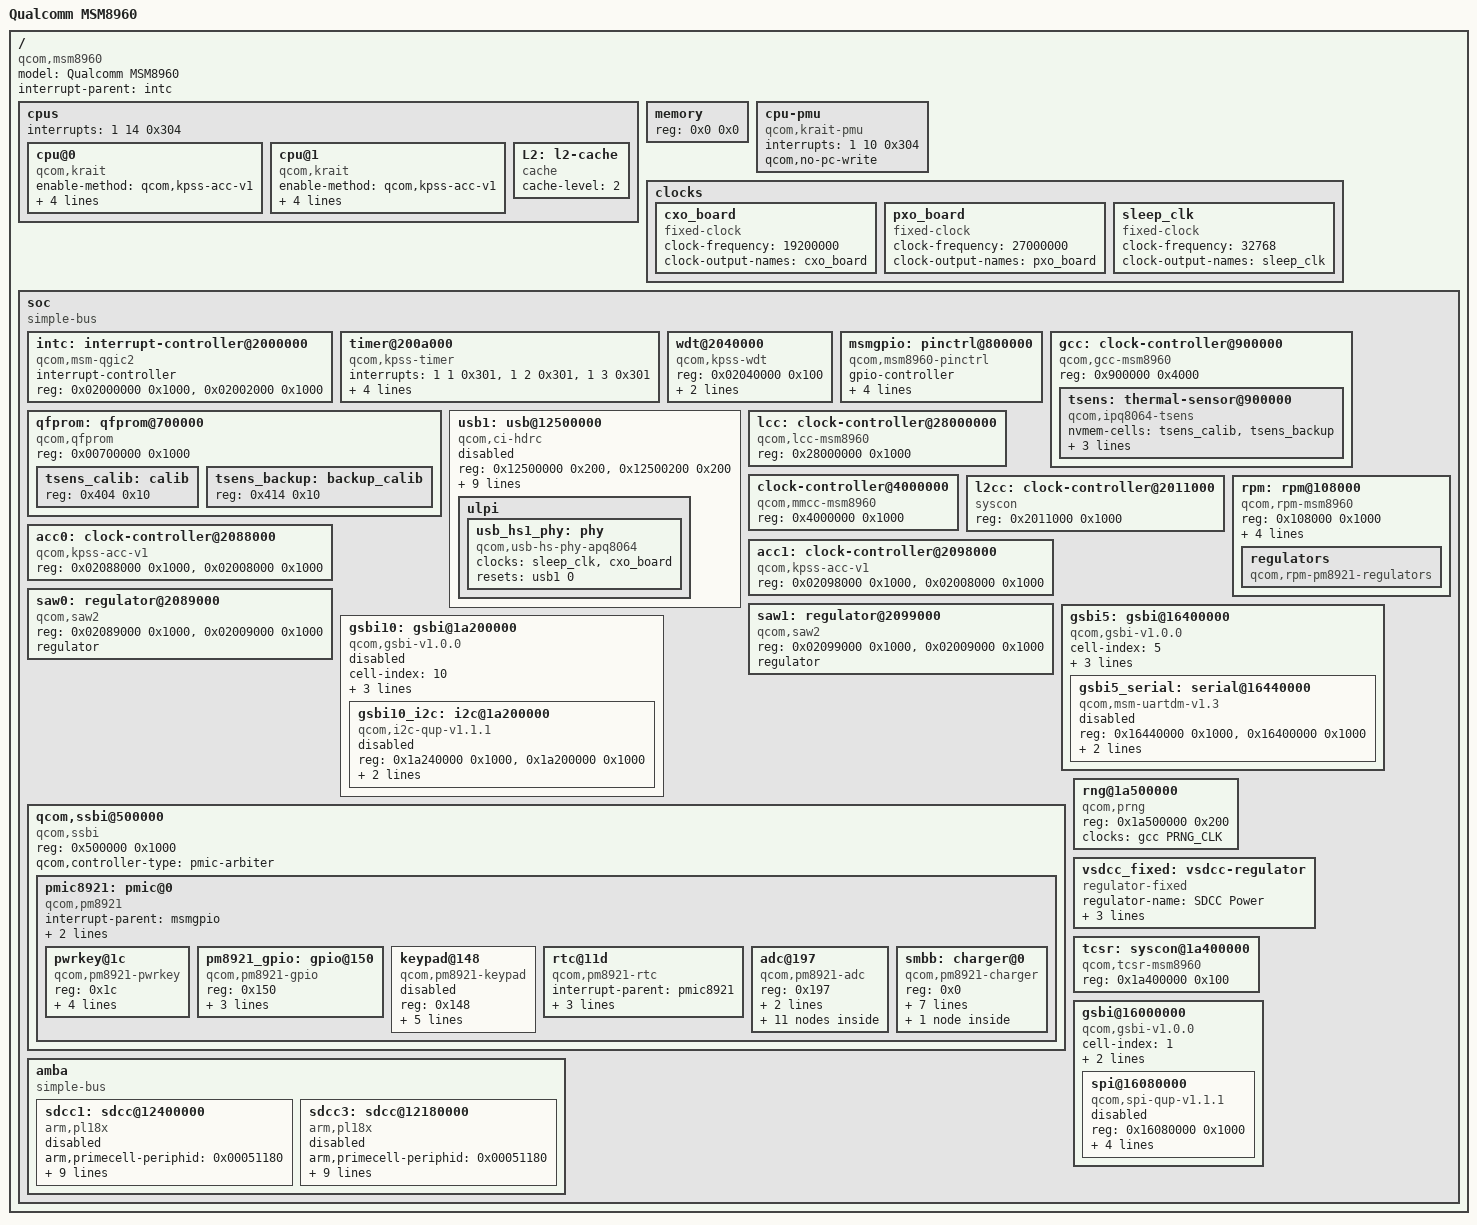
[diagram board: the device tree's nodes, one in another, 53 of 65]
// SPDX-License-Identifier: GPL-2.0
/dts-v1/;

#include <dt-bindings/interrupt-controller/arm-gic.h>
#include <dt-bindings/interrupt-controller/irq.h>
#include <dt-bindings/clock/qcom,gcc-msm8960.h>
#include <dt-bindings/reset/qcom,gcc-msm8960.h>
#include <dt-bindings/mfd/qcom-rpm.h>
#include <dt-bindings/soc/qcom,gsbi.h>

/ {
	#address-cells = <1>;
	#size-cells = <1>;
	model = "Qualcomm MSM8960";
	compatible = "qcom,msm8960";
	interrupt-parent = <&intc>;

	cpus {
		#address-cells = <1>;
		#size-cells = <0>;
		interrupts = <1 14 0x304>;

		cpu@0 {
			compatible = "qcom,krait";
			enable-method = "qcom,kpss-acc-v1";
			device_type = "cpu";
			reg = <0>;
			next-level-cache = <&L2>;
			qcom,acc = <&acc0>;
			qcom,saw = <&saw0>;
		};

		cpu@1 {
			compatible = "qcom,krait";
			enable-method = "qcom,kpss-acc-v1";
			device_type = "cpu";
			reg = <1>;
			next-level-cache = <&L2>;
			qcom,acc = <&acc1>;
			qcom,saw = <&saw1>;
		};

		L2: l2-cache {
			compatible = "cache";
			cache-level = <2>;
		};
	};

	memory {
		device_type = "memory";
		reg = <0x0 0x0>;
	};

	cpu-pmu {
		compatible = "qcom,krait-pmu";
		interrupts = <1 10 0x304>;
		qcom,no-pc-write;
	};

	clocks {
		cxo_board: cxo_board {
			compatible = "fixed-clock";
			#clock-cells = <0>;
			clock-frequency = <19200000>;
			clock-output-names = "cxo_board";
		};

		pxo_board: pxo_board {
			compatible = "fixed-clock";
			#clock-cells = <0>;
			clock-frequency = <27000000>;
			clock-output-names = "pxo_board";
		};

		sleep_clk: sleep_clk {
			compatible = "fixed-clock";
			#clock-cells = <0>;
			clock-frequency = <32768>;
			clock-output-names = "sleep_clk";
		};
	};

	soc: soc {
		#address-cells = <1>;
		#size-cells = <1>;
		ranges;
		compatible = "simple-bus";

		intc: interrupt-controller@2000000 {
			compatible = "qcom,msm-qgic2";
			interrupt-controller;
			#interrupt-cells = <3>;
			reg = <0x02000000 0x1000>,
			      <0x02002000 0x1000>;
		};

		timer@200a000 {
			compatible = "qcom,kpss-timer", "qcom,kpss-wdt-msm8960";
			interrupts = <1 1 0x301>,
				     <1 2 0x301>,
				     <1 3 0x301>;
			reg = <0x0200a000 0x100>;
			clocks = <&pxo_board>, <&sleep_clk>;
			clock-frequency = <27000000>;
			//		  <32768>;
			// clocks = <&wdt_osc 0>, <&sleep_clk 0>;
			clock-names = "pxo_board", "sleep_clk";
			cpu-offset = <0x80000>;
		};

		wdt@2040000 {
			compatible = "qcom,kpss-wdt", "qcom,kpss-wdt-msm8960";
			reg = <0x02040000 0x100>;
			clocks = <&pxo_board>;
			clock-names = "pxo_board";
			cpu-offset = <0x80000>;
		};

		// sleep_clk: wdt-sleep-clk {
		// 	compatible = "fixed-clock";
		// 	#clock-cells = <0>;
		// 	clock-frequency = <32768>;
		// 	clock-output-names = "wdt_sleep";
		// };

		msmgpio: pinctrl@800000 {
			compatible = "qcom,msm8960-pinctrl";
			gpio-controller;
			gpio-ranges = <&msmgpio 0 0 152>;
			#gpio-cells = <2>;
			interrupts = <0 16 0x4>;
			interrupt-controller;
			#interrupt-cells = <2>;
			reg = <0x800000 0x4000>;
		};

		qfprom: qfprom@700000 {
			compatible	= "qcom,qfprom";
			reg		= <0x00700000 0x1000>;
			#address-cells	= <1>;
			#size-cells	= <1>;
			ranges;
			tsens_calib: calib {
				reg = <0x404 0x10>;
			};
			tsens_backup: backup_calib {
				reg = <0x414 0x10>;
			};
		};

		gcc: clock-controller@900000 {
			compatible = "qcom,gcc-msm8960";
			#clock-cells = <1>;
			#reset-cells = <1>;
			reg = <0x900000 0x4000>;

			tsens: thermal-sensor@900000 {
				compatible = "qcom,ipq8064-tsens";
				nvmem-cells = <&tsens_calib>, <&tsens_backup>;
				nvmem-cell-names = "calib", "calib_backup";
				interrupts = <GIC_SPI 178 IRQ_TYPE_LEVEL_HIGH>;
				interrupt-names = "uplow";

				#qcom,sensors = <11>;
				#thermal-sensor-cells = <1>;
			};
		};

		usb1: usb@12500000 {
			compatible = "qcom,ci-hdrc";
			reg = <0x12500000 0x200>, 
			      <0x12500200 0x200>;
			interrupts = <GIC_SPI 100 IRQ_TYPE_LEVEL_HIGH>;
			clocks = <&gcc USB_HS1_XCVR_CLK>, <&gcc USB_HS1_H_CLK>;
			clock-names = "core", "iface";
			assigned-clocks = <&gcc USB_HS1_XCVR_CLK>;
			assigned-clock-rates = <60000000>;
			resets = <&gcc USB_HS1_RESET>;
			reset-names = "core";
			phy_type = "ulpi";
			ahb-burst-config = <0>;
			phys = <&usb_hs1_phy>;
			phy-names = "usb-phy";
			status = "disabled";
			#reset-cells = <1>;

			ulpi {
				usb_hs1_phy: phy {
					compatible = "qcom,usb-hs-phy-apq8064",
						     "qcom,usb-hs-phy";
					clocks = <&sleep_clk>, <&cxo_board>;
					clock-names = "sleep", "ref";
					resets = <&usb1 0>;
					reset-names = "por";
					#phy-cells = <0>;
				};
			};
		};

		lcc: clock-controller@28000000 {
			compatible = "qcom,lcc-msm8960";
			reg = <0x28000000 0x1000>;
			#clock-cells = <1>;
			#reset-cells = <1>;
		};

		clock-controller@4000000 {
			compatible = "qcom,mmcc-msm8960";
			reg = <0x4000000 0x1000>;
			#clock-cells = <1>;
			#reset-cells = <1>;
		};

		l2cc: clock-controller@2011000 {
			compatible	= "syscon";
			reg		= <0x2011000 0x1000>;
		};

		rpm: rpm@108000 {
			compatible	= "qcom,rpm-msm8960";
			reg		= <0x108000 0x1000>;
			qcom,ipc	= <&l2cc 0x8 2>;

			interrupts	= <0 19 IRQ_TYPE_EDGE_RISING>, <0 21 IRQ_TYPE_EDGE_RISING>, <0 22 IRQ_TYPE_EDGE_RISING>;
			interrupt-names	= "ack", "err", "wakeup";

			regulators {
				compatible = "qcom,rpm-pm8921-regulators";
			};
		};

		acc0: clock-controller@2088000 {
			compatible = "qcom,kpss-acc-v1";
			reg = <0x02088000 0x1000>, <0x02008000 0x1000>;
		};

		acc1: clock-controller@2098000 {
			compatible = "qcom,kpss-acc-v1";
			reg = <0x02098000 0x1000>, <0x02008000 0x1000>;
		};

		saw0: regulator@2089000 {
			compatible = "qcom,saw2";
			reg = <0x02089000 0x1000>, <0x02009000 0x1000>;
			regulator;
		};

		saw1: regulator@2099000 {
			compatible = "qcom,saw2";
			reg = <0x02099000 0x1000>, <0x02009000 0x1000>;
			regulator;
		};

		gsbi5: gsbi@16400000 {
			compatible = "qcom,gsbi-v1.0.0";
			cell-index = <5>;
			reg = <0x16400000 0x100>;
			clocks = <&gcc GSBI5_H_CLK>;
			clock-names = "iface";
			#address-cells = <1>;
			#size-cells = <1>;
			ranges;

			syscon-tcsr = <&tcsr>;

			gsbi5_serial: serial@16440000 {
				compatible = "qcom,msm-uartdm-v1.3", "qcom,msm-uartdm";
				reg = <0x16440000 0x1000>,
				      <0x16400000 0x1000>;
				interrupts = <0 154 IRQ_TYPE_EDGE_RISING>;
				clocks = <&gcc GSBI5_UART_CLK>, <&gcc GSBI5_H_CLK>;
				clock-names = "core", "iface";
				status = "disabled";
			};
		};

		gsbi10: gsbi@1a200000 {
			compatible = "qcom,gsbi-v1.0.0";
			cell-index = <10>;
			reg = <0x1a200000 0x100>;
			clocks = <&gcc GSBI10_H_CLK>;
			clock-names = "iface";
			#address-cells = <1>;
			#size-cells = <1>;
			ranges;
			status = "disabled";

			syscon-tcsr = <&tcsr>;

			gsbi10_i2c: i2c@1a200000 {
				compatible = "qcom,i2c-qup-v1.1.1";
				status = "disabled";
				reg = <0x1a240000 0x1000>,
				      <0x1a200000 0x1000>;
				interrupts = <0 192 IRQ_TYPE_EDGE_RISING>;
				clocks = <&gcc GSBI10_QUP_CLK>, <&gcc GSBI10_H_CLK>;
				clock-names = "core", "iface";
				status = "disabled";
			};
		};

		qcom,ssbi@500000 {
			compatible = "qcom,ssbi";
			reg = <0x500000 0x1000>;
			qcom,controller-type = "pmic-arbiter";

			pmic8921: pmic@0 {
				compatible = "qcom,pm8921";
				interrupt-parent = <&msmgpio>;
				interrupts = <104 8>;
				#interrupt-cells = <2>;
				interrupt-controller;
				#address-cells = <1>;
				#size-cells = <0>;

				pwrkey@1c {
					compatible = "qcom,pm8921-pwrkey";
					reg = <0x1c>;
					interrupt-parent = <&pmic8921>;
					interrupts = <50 1>, <51 1>;
					debounce = <15625>;
					pull-up;
				};

				pm8921_gpio: gpio@150 {

					compatible = "qcom,pm8921-gpio",
						     "qcom,ssbi-gpio";
					reg = <0x150>;
					interrupt-controller;
					#interrupt-cells = <2>;
					gpio-controller;
					gpio-ranges = <&pm8921_gpio 0 0 44>;
					#gpio-cells = <2>;

				};

				keypad@148 {
					compatible = "qcom,pm8921-keypad";
					reg = <0x148>;
					interrupt-parent = <&pmic8921>;
					interrupts = <74 1>, <75 1>;
					debounce = <15>;
					scan-delay = <32>;
					row-hold = <91500>;
					status ="disabled";
				};

				rtc@11d {
					compatible = "qcom,pm8921-rtc";
					interrupt-parent = <&pmic8921>;
					interrupts = <39 1>;
					reg = <0x11d>;
					allow-set-time;
				};

				adc@197 {
					compatible = "qcom,pm8921-adc";
					reg = <0x197>;
					interrupts-extended = <&pmic8921 76 IRQ_TYPE_EDGE_RISING>;
					#address-cells = <2>;
					#size-cells = <0>;
					#io-channel-cells = <2>;

					vcoin: adc-channel@0 {
						reg = <0x00 0x00>;
					};
					vbat: adc-channel@1 {
						reg = <0x00 0x01>;
					};
					dcin: adc-channel@2 {
						reg = <0x00 0x02>;
					};
					ichg: adc-channel@3 {
						reg = <0x00 0x03>;
					};
					vph_pwr: adc-channel@4 {
						reg = <0x00 0x04>;
					};
					usb_vbus: adc-channel@a {
						reg = <0x00 0x0a>;
					};
					die_temp: adc-channel@b {
						reg = <0x00 0x0b>;
					};
					ref_625mv: adc-channel@c {
						reg = <0x00 0x0c>;
					};
					ref_1250mv: adc-channel@d {
						reg = <0x00 0x0d>;
					};
					ref_325mv: adc-channel@e {
						reg = <0x00 0x0e>;
					};
					ref_muxoff: adc-channel@f {
						reg = <0x00 0x0f>;
					};
				};

				smbb: charger@0 {
					compatible = "qcom,pm8921-charger";
					reg = <0x0>;

					interrupt-parent = <&pmic8921>;
					interrupts =
						<8 1>, <9 1>, <10 1>, <11 1>, <12 1>, <13 1>,
						<14 1>, <15 1>, <16 1>, <17 1>, <18 1>, <19 1>,
						<20 1>, <21 1>, <22 1>, <23 1>, <24 1>, <25 1>,
						<26 1>, <27 1>, <28 1>, <29 1>, <30 1>, <31 1>,
						<40 1>, <41 1>, <42 1>, <43 1>, <44 1>, <45 1>,
						<47 1>;
					interrupt-names =
						"vcp", "chg-wdog", "vbat-ov", "usb-uv",
						"vbatdet-low", "bat-insert", "usb-ov", "usb-valid",
						"chg-trkl", "chg-fast", "loopchange", "chg-state",
						"chg-fail", "chg-done", "atc-fail", "atc-done",
						"vdd-loop", "course-det-low", "bat-temp-ok",
						"chg-gone", "bat-temp-cold", "chg-hot",
						"bat-temp-hot", "bat-remove","dc-uv", "dc-ov",
						"dc-valid", "psi", "batfet", "vbatdet", "vreg-ov";

					// usb-otg-in-supply = <&pm8941_5vs1>;

					qcom,disable-dc;
				// { "bat-present", smbb_bat_present_handler },

					chg_otg: otg-vbus { };
				};
			};
		};

		rng@1a500000 {
			compatible = "qcom,prng";
			reg = <0x1a500000 0x200>;
			clocks = <&gcc PRNG_CLK>;
			clock-names = "core";
		};

		/* Temporary fixed regulator */
		vsdcc_fixed: vsdcc-regulator {
			compatible = "regulator-fixed";
			regulator-name = "SDCC Power";
			regulator-min-microvolt = <2700000>;
			regulator-max-microvolt = <2700000>;
			regulator-always-on;
		};

		amba {
			compatible = "simple-bus";
			#address-cells = <1>;
			#size-cells = <1>;
			ranges;
			sdcc1: sdcc@12400000 {
				status		= "disabled";
				compatible	= "arm,pl18x", "arm,primecell";
				arm,primecell-periphid = <0x00051180>;
				reg		= <0x12400000 0x8000>;
				interrupts	= <GIC_SPI 104 IRQ_TYPE_LEVEL_HIGH>;
				interrupt-names	= "cmd_irq";
				clocks		= <&gcc SDC1_CLK>, <&gcc SDC1_H_CLK>;
				clock-names	= "mclk", "apb_pclk";
				bus-width	= <8>;
				max-frequency	= <96000000>;
				non-removable;
				cap-sd-highspeed;
				cap-mmc-highspeed;
				vmmc-supply = <&vsdcc_fixed>;
			};

			sdcc3: sdcc@12180000 {
				compatible	= "arm,pl18x", "arm,primecell";
				arm,primecell-periphid = <0x00051180>;
				status		= "disabled";
				reg		= <0x12180000 0x8000>;
				interrupts	= <GIC_SPI 102 IRQ_TYPE_LEVEL_HIGH>;
				interrupt-names	= "cmd_irq";
				clocks		= <&gcc SDC3_CLK>, <&gcc SDC3_H_CLK>;
				clock-names	= "mclk", "apb_pclk";
				bus-width	= <4>;
				cap-sd-highspeed;
				cap-mmc-highspeed;
				max-frequency	= <192000000>;
				no-1-8-v;
				vmmc-supply = <&vsdcc_fixed>;
			};
		};

		tcsr: syscon@1a400000 {
			compatible = "qcom,tcsr-msm8960", "syscon";
			reg = <0x1a400000 0x100>;
		};

		gsbi@16000000 {
			compatible = "qcom,gsbi-v1.0.0";
			cell-index = <1>;
			reg = <0x16000000 0x100>;
			clocks = <&gcc GSBI1_H_CLK>;
			clock-names = "iface";
			#address-cells = <1>;
			#size-cells = <1>;
			ranges;

			spi@16080000 {
				compatible = "qcom,spi-qup-v1.1.1";
				#address-cells = <1>;
				#size-cells = <0>;
				reg = <0x16080000 0x1000>;
				interrupts = <0 147 IRQ_TYPE_EDGE_RISING>;
				spi-max-frequency = <24000000>;
				cs-gpios = <&msmgpio 8 0>;

				clocks = <&gcc GSBI1_QUP_CLK>, <&gcc GSBI1_H_CLK>;
				clock-names = "core", "iface";
				status = "disabled";
			};
		};
	};
};
